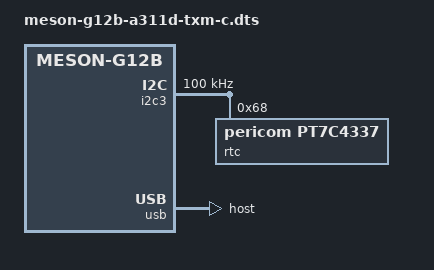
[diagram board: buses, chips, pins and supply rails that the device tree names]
// SPDX-License-Identifier: (GPL-2.0+ OR MIT)
/*
 * Copyright (c) 2019 BayLibre, SAS
 * Author: Neil Armstrong <narmstrong@baylibre.com>
 * Copyright (c) 2019 Christian Hewitt <christianshewitt@gmail.com>
 */

/dts-v1/;

#include "meson-g12b-a311d.dtsi"
#include "meson-txm-common.dtsi"
#include "meson-g12b-txm.dtsi"

/ {
	compatible = "khadas,vim3", "amlogic,a311d", "amlogic,g12b";
};

&i2c3 {
	status = "okay";
	clock-frequency = <100000>;
	pinctrl-0 = <&i2c3_sda_a_pins>, <&i2c3_sck_a_pins>;
	pinctrl-names = "default";

	rtc: rtc@68 {
		compatible = "pericom,pt7c4337";
		reg = <0x68>;
		#clock-cells = <0>;
		status = "okay";
	};
};

&usb {
	status = "okay";
	dr_mode = "host";
};

&ethmac {
	status = "disabled";
};

/*
 * The VIM3 on-board  MCU can mux the PCIe/USB3.0 shared differential
 * lines using a FUSB340TMX USB 3.1 SuperSpeed Data Switch between
 * an USB3.0 Type A connector and a M.2 Key M slot.
 * The PHY driving these differential lines is shared between
 * the USB3.0 controller and the PCIe Controller, thus only
 * a single controller can use it.
 * If the MCU is configured to mux the PCIe/USB3.0 differential lines
 * to the M.2 Key M slot, uncomment the following block to disable
 * USB3.0 from the USB Complex and enable the PCIe controller.
 * The End User is not expected to uncomment the following except for
 * testing purposes, but instead rely on the firmware/bootloader to
 * update these nodes accordingly if PCIe mode is selected by the MCU.
 */
/*

&usb {
	phys = <&usb2_phy0>, <&usb2_phy1>;
	phy-names = "usb2-phy0", "usb2-phy1";
};
 */
